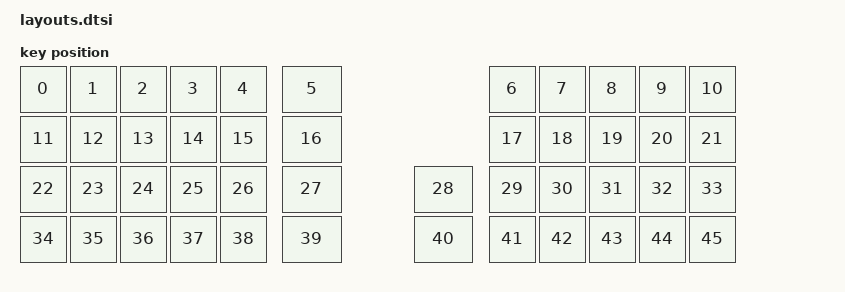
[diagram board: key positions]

#include <physical_layouts.dtsi>
/ {
    physical_layout0: physical_layout0 {
        compatible = "zmk,physical-layout";
        display-name = "Layout";
        keys
            = <&key_physical_attrs 100 100 (-50) 0 0 0 0>
			,<&key_physical_attrs 100 100 50 0 0 0 0>
			,<&key_physical_attrs 100 100 150 0 0 0 0>
			,<&key_physical_attrs 100 100 250 0 0 0 0>
			,<&key_physical_attrs 100 100 350 0 0 0 0>
			,<&key_physical_attrs 125 100 475 0 0 0 0>
			,<&key_physical_attrs 100 100 888 0 0 0 0>
			,<&key_physical_attrs 100 100 988 0 0 0 0>
			,<&key_physical_attrs 100 100 1088 0 0 0 0>
			,<&key_physical_attrs 100 100 1188 0 0 0 0>
			,<&key_physical_attrs 100 100 1288 0 0 0 0>
			,<&key_physical_attrs 100 100 (-50) 100 0 0 0>
			,<&key_physical_attrs 100 100 50 100 0 0 0>
			,<&key_physical_attrs 100 100 150 100 0 0 0>
			,<&key_physical_attrs 100 100 250 100 0 0 0>
			,<&key_physical_attrs 100 100 350 100 0 0 0>
			,<&key_physical_attrs 125 100 475 100 0 0 0>
			,<&key_physical_attrs 100 100 888 100 0 0 0>
			,<&key_physical_attrs 100 100 988 100 0 0 0>
			,<&key_physical_attrs 100 100 1088 100 0 0 0>
			,<&key_physical_attrs 100 100 1188 100 0 0 0>
			,<&key_physical_attrs 100 100 1288 100 0 0 0>
			,<&key_physical_attrs 100 100 (-50) 200 0 0 0>
			,<&key_physical_attrs 100 100 50 200 0 0 0>
			,<&key_physical_attrs 100 100 150 200 0 0 0>
			,<&key_physical_attrs 100 100 250 200 0 0 0>
			,<&key_physical_attrs 100 100 350 200 0 0 0>
			,<&key_physical_attrs 125 100 475 200 0 0 0>
			,<&key_physical_attrs 125 100 738 200 0 0 0>
			,<&key_physical_attrs 100 100 888 200 0 0 0>
			,<&key_physical_attrs 100 100 988 200 0 0 0>
			,<&key_physical_attrs 100 100 1088 200 0 0 0>
			,<&key_physical_attrs 100 100 1188 200 0 0 0>
			,<&key_physical_attrs 100 100 1288 200 0 0 0>
			,<&key_physical_attrs 100 100 (-50) 300 0 0 0>
			,<&key_physical_attrs 100 100 50 300 0 0 0>
			,<&key_physical_attrs 100 100 150 300 0 0 0>
			,<&key_physical_attrs 100 100 250 300 0 0 0>
			,<&key_physical_attrs 100 100 350 300 0 0 0>
			,<&key_physical_attrs 125 100 475 300 0 0 0>
			,<&key_physical_attrs 125 100 738 300 0 0 0>
			,<&key_physical_attrs 100 100 888 300 0 0 0>
			,<&key_physical_attrs 100 100 988 300 0 0 0>
			,<&key_physical_attrs 100 100 1088 300 0 0 0>
			,<&key_physical_attrs 100 100 1188 300 0 0 0>
			,<&key_physical_attrs 100 100 1288 300 0 0 0>
            ;
    };
};
    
